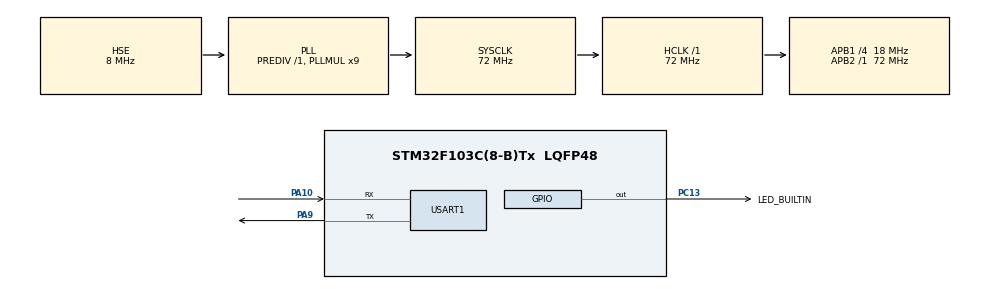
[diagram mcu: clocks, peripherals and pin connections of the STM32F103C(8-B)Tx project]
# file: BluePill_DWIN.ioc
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Mcu.Family=STM32F1
Mcu.Name=STM32F103C(8-B)Tx
Mcu.Package=LQFP48
NVIC.PriorityGroup=NVIC_PRIORITYGROUP_4
NVIC.USART1_IRQn=true\:0\:0\:false\:false\:true\:true\:true\:true
PA10.Mode=Asynchronous
PA10.Signal=USART1_RX
PA13.Mode=Serial_Wire
PA13.Signal=SYS_JTMS-SWDIO
PA14.Mode=Serial_Wire
PA14.Signal=SYS_JTCK-SWCLK
PA9.Mode=Asynchronous
PA9.Signal=USART1_TX
PC13-TAMPER-RTC.GPIO_Label=LED_BUILTIN
PC13-TAMPER-RTC.Signal=GPIO_Output
PD0-OSC_IN.Mode=HSE-External-Oscillator
PD0-OSC_IN.Signal=RCC_OSC_IN
PD1-OSC_OUT.Mode=HSE-External-Oscillator
PD1-OSC_OUT.Signal=RCC_OSC_OUT
ProjectManager.HeapSize=0x200
ProjectManager.StackSize=0x400
ProjectManager.TargetToolchain=CMake
RCC.AHBFreq_Value=72000000
RCC.APB1CLKDivider=RCC_HCLK_DIV4
RCC.APB1Freq_Value=18000000
RCC.APB1TimFreq_Value=36000000
RCC.APB2Freq_Value=72000000
RCC.APB2TimFreq_Value=72000000
RCC.HCLKFreq_Value=72000000
RCC.PLLMUL=RCC_PLL_MUL9
RCC.PLLSourceVirtual=RCC_PLLSOURCE_HSE
RCC.SYSCLKFreq_VALUE=72000000
RCC.SYSCLKSource=RCC_SYSCLKSOURCE_PLLCLK
RCC.USBFreq_Value=72000000
USART1.VirtualMode=VM_ASYNC
board=custom

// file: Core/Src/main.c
/* USER CODE BEGIN Header */
/**
  ******************************************************************************
  * @file           : main.c
  * @brief          : Main program body
  ******************************************************************************
  * @attention
  *
  * Copyright (c) 2025 STMicroelectronics.
  * All rights reserved.
  *
  * This software is licensed under terms that can be found in the LICENSE file
  * in the root directory of this software component.
  * If no LICENSE file comes with this software, it is provided AS-IS.
  *
  ******************************************************************************
  */
/* USER CODE END Header */
#include "main.h"

/* USER CODE BEGIN Includes */
#include "dwin.h"
#include "dwin_port_stm32.h"
#include "stm32f1xx_hal.h"
/* USER CODE END Includes */

UART_HandleTypeDef huart1;

/* USER CODE BEGIN PV */
static Dwin dwin;
static DwinStm32Port dport;

/* USER CODE END PV */

void SystemClock_Config(void);
static void MX_GPIO_Init(void);
static void MX_USART1_UART_Init(void);
/* USER CODE BEGIN PFP */
/* DWIN hooks (TX via HAL; RX handled by ISR queue) */
static size_t tx_write(const uint8_t* d, size_t n) { return dwin_stm32_tx(&dport, d, n, 1000); }
static int rx_read(uint8_t *d, size_t n) { (void)d; (void)n; return 0; }
static int rx_avail(void) { return 0; }
static uint32_t tick_ms(void) { return HAL_GetTick(); }
static void log_fn(const char* s) { (void)s; /* putchar/printf if you wish */ }

/* Minimal callbacks: keep ISR-light; do work in loop() via flags */
static volatile uint8_t  g_touch_flag = 0;
static volatile uint16_t g_last_vp    = 0;
static volatile uint8_t  g_last_ev    = 0;

static void on_touch(Dwin *ctx, uint16_t vp, uint8_t ev)
{
  (void)ctx;
  g_last_vp = vp;
  g_last_ev = ev;
  if(vp==0x2008)g_touch_flag = 1;  /* handled in loop() */
}

static void on_frame(Dwin *ctx, const uint8_t *frame, size_t len)
{
  (void)ctx; (void)frame; (void)len; /* optional: add hexdump if needed */
}

/* USER CODE END PFP */

int main(void)
{

  /* MCU Configuration--------------------------------------------------------*/

  /* Reset of all peripherals, Initializes the Flash interface and the Systick. */
  HAL_Init();

  /* Configure the system clock */
  SystemClock_Config();

  /* Initialize all configured peripherals */
  MX_GPIO_Init();
  MX_USART1_UART_Init();
  /* USER CODE BEGIN 2 */

  /* Bind DWIN to HAL UART (ISR queue) */
  dwin_init(&dwin, tx_write, rx_read, rx_avail, tick_ms, log_fn);
  dwin_use_isr_queue(&dwin, 1);
  dwin_use_crc(&dwin, 0); /* set 1 if your HMI requires TX CRC */
  dwin_set_touch_callback(&dwin, on_touch);
  dwin_set_frame_callback(&dwin, on_frame);

  dwin_stm32_attach(&dport, &dwin, &huart1);
  dwin_stm32_begin(&dport);  /* arms HAL_UART_Receive_IT for 1-byte RX */

  /* Minimal UI actions */
  /* Page transitions */
  dwin_set_page(&dwin, 1);HAL_Delay(1000);
  dwin_set_page(&dwin, 0);
  /* Set Brightness */
  dwin_set_brightness(&dwin, 85);HAL_Delay(10);
  /* Write some data */
  dwin_write_text(&dwin, 0x5000, "Hello DWIN (STM32)");HAL_Delay(10);
  dwin_write_u16(&dwin, 0x2000, 123);HAL_Delay(10);
  dwin_write_float(&dwin, 0x2004, 45.67f);HAL_Delay(10);
  /* Set Font Size */
  dwin_set_font_size(&dwin, 0x7000, 22);HAL_Delay(10);
  /* Set Date/Time */
  dwin_rtc_write(&dwin, 2025, 05, 21, 17, 25, 13);HAL_Delay(10);
  /* Beep */
  // dwin_beep_1s(&dwin); HAL_Delay(10);
  /* Set Color */
  dwin_set_color565(&dwin, 0x7000, 0xfd00);HAL_Delay(10);

  /* USER CODE END 2 */

  /* Infinite loop */
  while (1)
  {

    /* USER CODE BEGIN 3 */
    dwin_poll(&dwin);                         /* consume bytes from ISR queue */
    if (g_touch_flag) {
      g_touch_flag = 0;
      HAL_GPIO_TogglePin(GPIOC, GPIO_PIN_13);           /* visual feedback */
      dwin_write_text(&dwin, 0x5000, "Touched!");      /* tiny demo action */
    }
  }
  /* USER CODE END 3 */
}

void SystemClock_Config(void)
{
  RCC_OscInitTypeDef RCC_OscInitStruct = {0};
  RCC_ClkInitTypeDef RCC_ClkInitStruct = {0};

  /** Initializes the RCC Oscillators according to the specified parameters
  * in the RCC_OscInitTypeDef structure.
  */
  RCC_OscInitStruct.OscillatorType = RCC_OSCILLATORTYPE_HSE;
  RCC_OscInitStruct.HSEState = RCC_HSE_ON;
  RCC_OscInitStruct.HSEPredivValue = RCC_HSE_PREDIV_DIV1;
  RCC_OscInitStruct.HSIState = RCC_HSI_ON;
  RCC_OscInitStruct.PLL.PLLState = RCC_PLL_ON;
  RCC_OscInitStruct.PLL.PLLSource = RCC_PLLSOURCE_HSE;
  RCC_OscInitStruct.PLL.PLLMUL = RCC_PLL_MUL9;
  if (HAL_RCC_OscConfig(&RCC_OscInitStruct) != HAL_OK)
  {
    Error_Handler();
  }

  /** Initializes the CPU, AHB and APB buses clocks
  */
  RCC_ClkInitStruct.ClockType = RCC_CLOCKTYPE_HCLK|RCC_CLOCKTYPE_SYSCLK
                              |RCC_CLOCKTYPE_PCLK1|RCC_CLOCKTYPE_PCLK2;
  RCC_ClkInitStruct.SYSCLKSource = RCC_SYSCLKSOURCE_PLLCLK;
  RCC_ClkInitStruct.AHBCLKDivider = RCC_SYSCLK_DIV1;
  RCC_ClkInitStruct.APB1CLKDivider = RCC_HCLK_DIV4;
  RCC_ClkInitStruct.APB2CLKDivider = RCC_HCLK_DIV1;

  if (HAL_RCC_ClockConfig(&RCC_ClkInitStruct, FLASH_LATENCY_2) != HAL_OK)
  {
    Error_Handler();
  }
}

static void MX_USART1_UART_Init(void)
{

  huart1.Instance = USART1;
  huart1.Init.BaudRate = 115200;
  huart1.Init.WordLength = UART_WORDLENGTH_8B;
  huart1.Init.StopBits = UART_STOPBITS_1;
  huart1.Init.Parity = UART_PARITY_NONE;
  huart1.Init.Mode = UART_MODE_TX_RX;
  huart1.Init.HwFlowCtl = UART_HWCONTROL_NONE;
  huart1.Init.OverSampling = UART_OVERSAMPLING_16;
  if (HAL_UART_Init(&huart1) != HAL_OK)
  {
    Error_Handler();
  }

}

static void MX_GPIO_Init(void)
{
  GPIO_InitTypeDef GPIO_InitStruct = {0};

  /* GPIO Ports Clock Enable */
  __HAL_RCC_GPIOC_CLK_ENABLE();
  __HAL_RCC_GPIOD_CLK_ENABLE();
  __HAL_RCC_GPIOA_CLK_ENABLE();

  /*Configure GPIO pin Output Level */
  HAL_GPIO_WritePin(LED_BUILTIN_GPIO_Port, LED_BUILTIN_Pin, GPIO_PIN_RESET);

  /*Configure GPIO pin : LED_BUILTIN_Pin */
  GPIO_InitStruct.Pin = LED_BUILTIN_Pin;
  GPIO_InitStruct.Mode = GPIO_MODE_OUTPUT_PP;
  GPIO_InitStruct.Pull = GPIO_NOPULL;
  GPIO_InitStruct.Speed = GPIO_SPEED_FREQ_LOW;
  HAL_GPIO_Init(LED_BUILTIN_GPIO_Port, &GPIO_InitStruct);

}

/* USER CODE BEGIN 4 */
void HAL_UART_RxCpltCallback(UART_HandleTypeDef *huart)
{
  dwin_stm32_rx_byte_isr(huart);
}

/* USER CODE END 4 */

void Error_Handler(void)
{
  __disable_irq();
  while (1)
  {
  }
}
